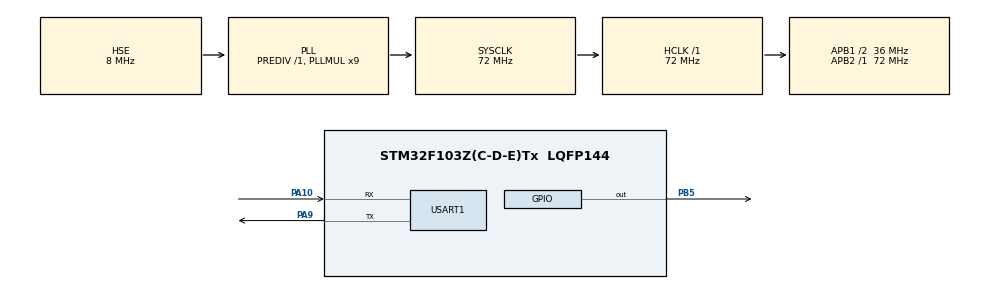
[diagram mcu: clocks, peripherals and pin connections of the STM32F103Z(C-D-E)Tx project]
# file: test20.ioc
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Mcu.Family=STM32F1
Mcu.Name=STM32F103Z(C-D-E)Tx
Mcu.Package=LQFP144
NVIC.PriorityGroup=NVIC_PRIORITYGROUP_4
NVIC.RTC_Alarm_IRQn=true\:0\:0\:false\:false\:true\:true\:true\:true
NVIC.RTC_IRQn=true\:0\:0\:false\:false\:true\:true\:true\:true
NVIC.USART1_IRQn=true\:0\:0\:false\:false\:true\:true\:true\:true
OSC_IN.Mode=HSE-External-Oscillator
OSC_IN.Signal=RCC_OSC_IN
OSC_OUT.Mode=HSE-External-Oscillator
OSC_OUT.Signal=RCC_OSC_OUT
PA10.Mode=Asynchronous
PA10.Signal=USART1_RX
PA13.Mode=Serial_Wire
PA13.Signal=SYS_JTMS-SWDIO
PA14.Mode=Serial_Wire
PA14.Signal=SYS_JTCK-SWCLK
PA9.Mode=Asynchronous
PA9.Signal=USART1_TX
PB5.GPIO_PuPd=GPIO_PULLUP
PB5.GPIO_Speed=GPIO_SPEED_FREQ_HIGH
PB5.PinState=GPIO_PIN_SET
PB5.Signal=GPIO_Output
PC14-OSC32_IN.Mode=LSE-External-Oscillator
PC14-OSC32_IN.Signal=RCC_OSC32_IN
PC15-OSC32_OUT.Mode=LSE-External-Oscillator
PC15-OSC32_OUT.Signal=RCC_OSC32_OUT
ProjectManager.HeapSize=0x200
ProjectManager.StackSize=0x400
ProjectManager.TargetToolchain=MDK-ARM V5.32
RCC.AHBFreq_Value=72000000
RCC.APB1CLKDivider=RCC_HCLK_DIV2
RCC.APB1Freq_Value=36000000
RCC.APB1TimFreq_Value=72000000
RCC.APB2Freq_Value=72000000
RCC.APB2TimFreq_Value=72000000
RCC.HCLKFreq_Value=72000000
RCC.PLLMUL=RCC_PLL_MUL9
RCC.PLLSourceVirtual=RCC_PLLSOURCE_HSE
RCC.RTCClockSelection=RCC_RTCCLKSOURCE_LSE
RCC.SYSCLKFreq_VALUE=72000000
RCC.SYSCLKSource=RCC_SYSCLKSOURCE_PLLCLK
RCC.USBFreq_Value=72000000
RTC.Date=30
RTC.Hours=10
RTC.Minutes=20
RTC.Month=RTC_MONTH_NOVEMBER
RTC.Seconds=30
RTC.WeekDay=RTC_WEEKDAY_THURSDAY
RTC.Year=23
USART1.VirtualMode=VM_ASYNC
VP_RTC_VS_RTC_Activate.Mode=RTC_Enabled
VP_RTC_VS_RTC_Calendar.Mode=RTC_Calendar
board=custom

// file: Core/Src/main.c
/* USER CODE BEGIN Header */
/**
 ******************************************************************************
 * @file           : main.c
 * @brief          : Main program body
 ******************************************************************************
 * @attention
 *
 * Copyright (c) 2023 STMicroelectronics.
 * All rights reserved.
 *
 * This software is licensed under terms that can be found in the LICENSE file
 * in the root directory of this software component.
 * If no LICENSE file comes with this software, it is provided AS-IS.
 *
 ******************************************************************************
 */
/* USER CODE END Header */
#include "main.h"
#include "rtc.h"
#include "usart.h"
#include "gpio.h"

/* USER CODE BEGIN Includes */
#include <stdio.h>
/* USER CODE END Includes */

/* USER CODE BEGIN PM */
//RTC结构体变量
RTC_TimeTypeDef T; //时间结构体
RTC_DateTypeDef D; //日期结构体

/* USER CODE END PM */

/* USER CODE BEGIN PV */
void HAL_RTCEx_RTCEventCallback(RTC_HandleTypeDef *hrtc)
{
  HAL_GPIO_TogglePin(GPIOB, GPIO_PIN_5);
}
/* USER CODE END PV */

void SystemClock_Config(void);

int main(void)
{

  /* MCU Configuration--------------------------------------------------------*/

  /* Reset of all peripherals, Initializes the Flash interface and the Systick. */
  HAL_Init();

  /* Configure the system clock */
  SystemClock_Config();

  /* Initialize all configured peripherals */
  MX_GPIO_Init();
  MX_RTC_Init();
  MX_USART1_UART_Init();

  /* Infinite loop */
  while (1)
  {
    HAL_RTC_GetTime(&hrtc, &T, RTC_FORMAT_BIN);
    HAL_RTC_GetDate(&hrtc, &D, RTC_FORMAT_BIN); // 时间和日期必须同时Get，否则时间无法正常计数
    char text[50];
    sprintf(text,"\nTime: %02d-%02d-%02d\nDate: %02d-%02d-%02d",T.Hours,T.Minutes,T.Seconds,D.Year,D.Month,D.Date);//显示时间
    HAL_UART_Transmit(&huart1, (uint8_t *)text, 43, 50);
    HAL_Delay(1000); //延时1秒
  }
}

void SystemClock_Config(void)
{
  RCC_OscInitTypeDef RCC_OscInitStruct = {0};
  RCC_ClkInitTypeDef RCC_ClkInitStruct = {0};
  RCC_PeriphCLKInitTypeDef PeriphClkInit = {0};

  /** Initializes the RCC Oscillators according to the specified parameters
   * in the RCC_OscInitTypeDef structure.
   */
  RCC_OscInitStruct.OscillatorType = RCC_OSCILLATORTYPE_HSE | RCC_OSCILLATORTYPE_LSE;
  RCC_OscInitStruct.HSEState = RCC_HSE_ON;
  RCC_OscInitStruct.HSEPredivValue = RCC_HSE_PREDIV_DIV1;
  RCC_OscInitStruct.LSEState = RCC_LSE_ON;
  RCC_OscInitStruct.HSIState = RCC_HSI_ON;
  RCC_OscInitStruct.PLL.PLLState = RCC_PLL_ON;
  RCC_OscInitStruct.PLL.PLLSource = RCC_PLLSOURCE_HSE;
  RCC_OscInitStruct.PLL.PLLMUL = RCC_PLL_MUL9;
  if (HAL_RCC_OscConfig(&RCC_OscInitStruct) != HAL_OK)
  {
    Error_Handler();
  }

  /** Initializes the CPU, AHB and APB buses clocks
   */
  RCC_ClkInitStruct.ClockType = RCC_CLOCKTYPE_HCLK | RCC_CLOCKTYPE_SYSCLK | RCC_CLOCKTYPE_PCLK1 | RCC_CLOCKTYPE_PCLK2;
  RCC_ClkInitStruct.SYSCLKSource = RCC_SYSCLKSOURCE_PLLCLK;
  RCC_ClkInitStruct.AHBCLKDivider = RCC_SYSCLK_DIV1;
  RCC_ClkInitStruct.APB1CLKDivider = RCC_HCLK_DIV2;
  RCC_ClkInitStruct.APB2CLKDivider = RCC_HCLK_DIV1;

  if (HAL_RCC_ClockConfig(&RCC_ClkInitStruct, FLASH_LATENCY_2) != HAL_OK)
  {
    Error_Handler();
  }
  PeriphClkInit.PeriphClockSelection = RCC_PERIPHCLK_RTC;
  PeriphClkInit.RTCClockSelection = RCC_RTCCLKSOURCE_LSE;
  if (HAL_RCCEx_PeriphCLKConfig(&PeriphClkInit) != HAL_OK)
  {
    Error_Handler();
  }
}

void Error_Handler(void)
{
  __disable_irq();
  while (1)
  {
  }
}
